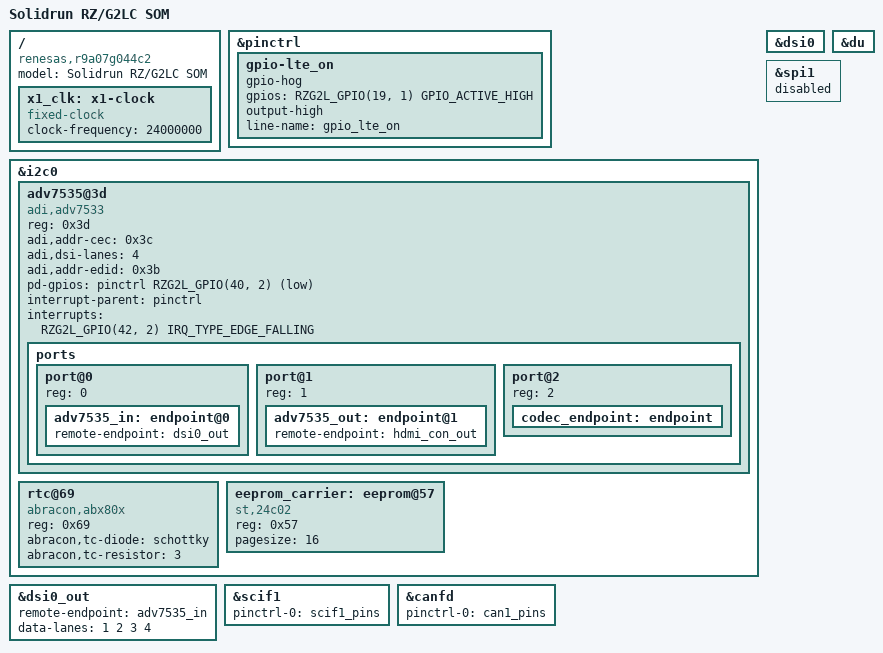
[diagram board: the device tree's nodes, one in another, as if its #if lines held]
// SPDX-License-Identifier: (GPL-2.0-only OR BSD-2-Clause)
/*
 * Device Tree Source for the RZ/G2LC Solidrun SOM
 *
 * Copyright (C) 2021 Renesas Electronics Corp.
 */

#include <dt-bindings/gpio/gpio.h>
#include <dt-bindings/pinctrl/rzg2l-pinctrl.h>

/*
 * DIP-Switch SW1 setting on SoM
 * 1 : High; 0: Low
 * SW1-2 : SW_SD0_DEV_SEL	(1: eMMC; 0: uSD)
 * SW1-3 : SW_SCIF_CAN		(1: CAN1; 0: SCIF1)
 * SW1-4 : SW_RSPI_CAN		(1: CAN1; 0: RSPI1)
 * Please change below macros according to SW1 setting
 */

#define SW_SD0_DEV_SEL	0

#define SW_SCIF_CAN	0
#if (SW_SCIF_CAN)
/* Due to HW routing, SW_RSPI_CAN is always 0 when SW_SCIF_CAN is set to 1 */
#define SW_RSPI_CAN	0
#define SCIF1_GPT3	1 /* Enable GPT3 when SCIF1 disabled */
#else
/* Please set SW_RSPI_CAN. Default value is 1 */
#define SW_RSPI_CAN	1
#endif

#if (SW_SCIF_CAN & SW_RSPI_CAN)
#error "Can not set 1 to both SW_SCIF_CAN and SW_RSPI_CAN due to HW routing"
#endif

/* comment the #define statement to disable SCIF1 (SER0) on PMOD1 (CN7) */
#define PMOD1_SER0	1
/* Select function support POEGD (1: enabled, 0 : disabled) */
#define POEGD_SUPPORT	1

/dts-v1/;
#include "rzg2lc-sr-som.dtsi"
#include "rzg2lc-sr-pinfunction.dtsi"

/ {
  model = "Solidrun RZ/G2LC SOM";
  compatible = "renesas,r9a07g044c2", "renesas,r9a07g044";

  x1_clk: x1-clock {
		compatible = "fixed-clock";
		#clock-cells = <0>;
		clock-frequency = <24000000>;
	};
};

&pinctrl {
  gpio-lte_on {
    gpio-hog;
    gpios = <RZG2L_GPIO(19, 1) GPIO_ACTIVE_HIGH>;
    output-high;
    line-name = "gpio_lte_on";
  };
};

&i2c0 {
	adv7535@3d {
		compatible = "adi,adv7533";
		reg = <0x3d>;
		adi,addr-cec = <0x3c>;
		adi,dsi-lanes = <4>;
		adi,addr-edid = <0x3b>;
		pd-gpios = <&pinctrl RZG2L_GPIO(40, 2) GPIO_ACTIVE_LOW>; // ADV_PD / DSI_EN J9-34 / P40_2
		interrupt-parent = <&pinctrl>;
		interrupts = <RZG2L_GPIO(42, 2) IRQ_TYPE_EDGE_FALLING>; // DSI_TS_nINT J5001-43 P42_2
		status = "okay";

		ports {
			#address-cells = <1>;
			#size-cells = <0>;

			port@0 {
				reg = <0>;
				adv7535_in: endpoint@0 {
					remote-endpoint = <&dsi0_out>;
				};
			};

			port@1 {
				reg = <1>;
				adv7535_out: endpoint@1 {
					remote-endpoint = <&hdmi_con_out>;
				};
			};

			port@2 {
				reg = <2>;
				codec_endpoint: endpoint {
					/* Audio signals not connected. */
				};
			};
		};
	};

	rtc@69 {
		compatible = "abracon,abx80x";
		reg = <0x69>;
		abracon,tc-diode = "schottky";
		abracon,tc-resistor = <3>;
	};

  eeprom_carrier: eeprom@57 {
    compatible = "st,24c02", "atmel,24c02";
    reg = <0x57>;
    pagesize = <16>;
  };

};

&dsi0 {
	status = "okay";
};

&dsi0_out {
	remote-endpoint = <&adv7535_in>;
	data-lanes = <1 2 3 4>;
};

&du {
	status = "okay";
};

/*
 * To enable SCIF1 (SER0) on PMOD1 (CN7), On connector board
 * SW1 should be at position 2->3 so that SER0_CTS# line is activated
 * SW2 should be at position 2->3 so that SER0_TX line is activated
 * SW3 should be at position 2->3 so that SER0_RX line is activated
 * SW4 should be at position 2->3 so that SER0_RTS# line is activated
 */
#if (!SW_SCIF_CAN && PMOD1_SER0 && !SCIF1_GPT3)
&scif1 {
	pinctrl-0 = <&scif1_pins>;
	pinctrl-names = "default";

	//uart-has-rtscts;
	status = "okay";
};
#endif

#if ((SW_SCIF_CAN || SW_RSPI_CAN) && !MTU3_PWM_SUPPORT)
&canfd {
	pinctrl-0 = <&can1_pins>;
	/delete-node/ channel0;
};
#else
&canfd {
	/delete-property/ pinctrl-0;
	/delete-property/ pinctrl-names;
	status = "disabled";
};
#endif

#if (SW_RSPI_CAN)
&spi1 {
	/delete-property/ pinctrl-0;
	/delete-property/ pinctrl-names;
	status = "disabled";
};
#endif
